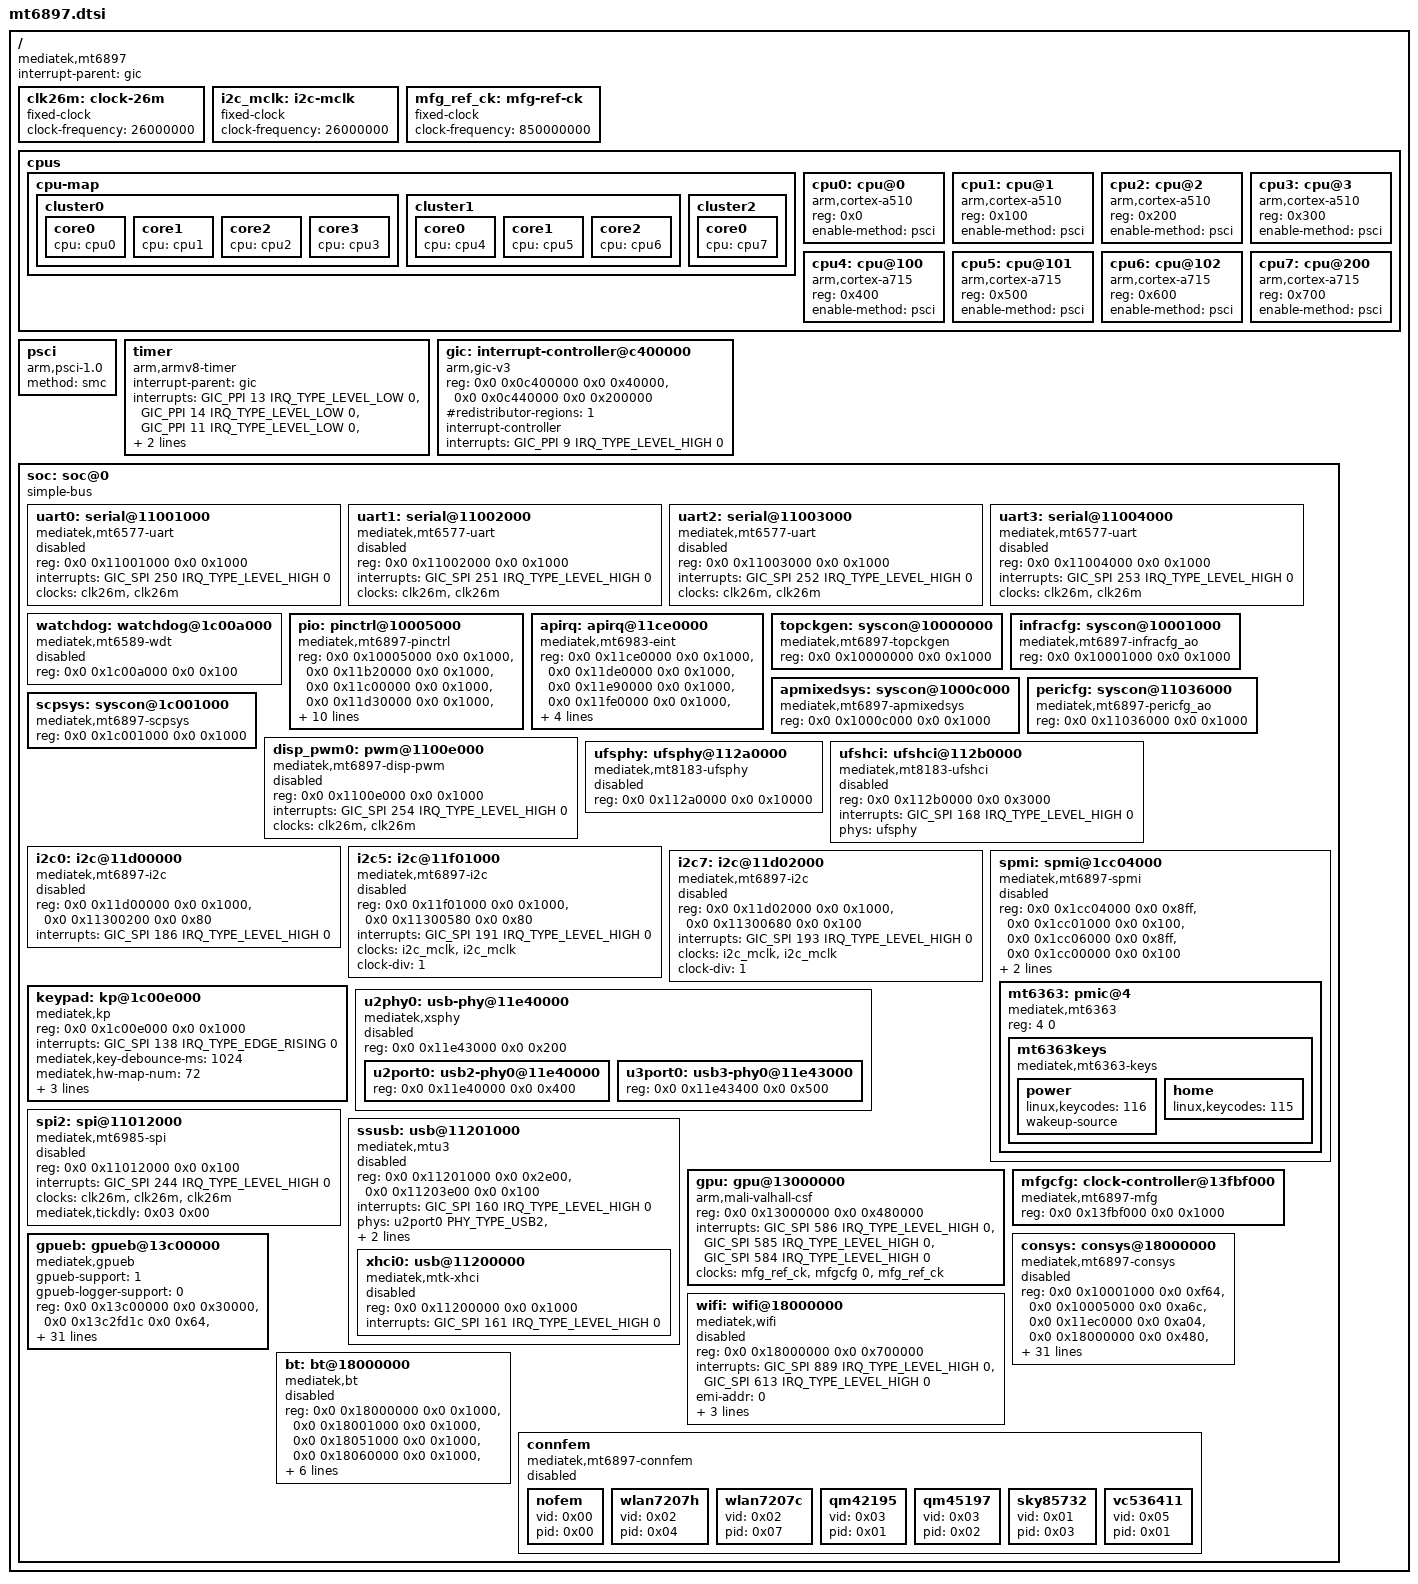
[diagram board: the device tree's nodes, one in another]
// SPDX-License-Identifier: GPL-2.0 OR BSD-3-Clause
/*
 * MediaTek MT6897 (MT8792) SoC — mainline bring-up, stage S1.
 *
 * 每一个数值都取自设备 bootloader 实际传入的 FDT
 * (reports/20260910-recovery/board.dtb)，那是最可信的硬件事实源。
 * 不确定的（时钟树编号、引脚表、电源域编号）先不写，等驱动落地再补。
 *
 * 单元数：厂商 DTB 的 / 与 /soc 都是 #address-cells=2 / #size-cells=2
 * （MT6895 主线移植用 1/1，直接套到这颗 SoC 上会错），本文件跟随厂商。
 * 中断单元数同理是 4（末位是 0），不是主线的 3。
 *
 * ⚠️ GIC 基址有家族惯例与本机的冲突，见下方 gic 节点的注释。
 */

#include <dt-bindings/interrupt-controller/arm-gic.h>
#include <dt-bindings/interrupt-controller/irq.h>
#include <dt-bindings/phy/phy.h>
#include <dt-bindings/gpio/gpio.h>

/ {
	compatible = "mediatek,mt6897";
	#address-cells = <2>;
	#size-cells = <2>;

	interrupt-parent = <&gic>;

	/* 没有时钟驱动前的临时时钟源：给 UART 用，让早期控制台能出字 */
	clk26m: clock-26m {
		compatible = "fixed-clock";
		#clock-cells = <0>;
		clock-frequency = <26000000>;
	};

	/*
	 * I2C 模块时钟占位（主线暂无 MT6897 topckgen 驱动）。
	 * i2c-mt65xx 用 clk_get_rate("main") 算分频：SCL = f_real / (2 * div)，
	 * 而 div 是按 f_assumed 算出来的 ⇒ SCL_actual = 目标频率 × f_real / f_assumed。
	 * 故意把 f_assumed 取大：真实模块时钟若比它低，实际 SCL 只会更慢（安全方向）。
	 * 真实频率待 recovery 侧 /sys/kernel/debug/clk/clk_summary 实测后修正。
	 */
	i2c_mclk: i2c-mclk {
		compatible = "fixed-clock";
		#clock-cells = <0>;
		clock-frequency = <26000000>;
	};

	/*
	 * MFG 参考时钟：mfgcfg BG3D gate 的父时钟。
	 * 主线暂无 MT6897 topckgen 驱动，先用 fixed-clock 占位（LK/preloader
	 * 已经把 MFGPLL 跑起来了，真实频率约 850MHz）。
	 */
	mfg_ref_ck: mfg-ref-ck {
		compatible = "fixed-clock";
		#clock-cells = <0>;
		clock-frequency = <850000000>;
	};

	cpus {
		#address-cells = <1>;
		#size-cells = <0>;

		cpu-map {
			cluster0 {
				core0 { cpu = <&cpu0>; };
				core1 { cpu = <&cpu1>; };
				core2 { cpu = <&cpu2>; };
				core3 { cpu = <&cpu3>; };
			};
			cluster1 {
				core0 { cpu = <&cpu4>; };
				core1 { cpu = <&cpu5>; };
				core2 { cpu = <&cpu6>; };
			};
			cluster2 {
				core0 { cpu = <&cpu7>; };
			};
		};

		/* 4x Cortex-A510（厂商 DTB 里每个核各占一个 cluster 位） */
		cpu0: cpu@0 {
			device_type = "cpu";
			compatible = "arm,cortex-a510";
			reg = <0x0>;
			enable-method = "psci";
		};
		cpu1: cpu@1 {
			device_type = "cpu";
			compatible = "arm,cortex-a510";
			reg = <0x100>;
			enable-method = "psci";
		};
		cpu2: cpu@2 {
			device_type = "cpu";
			compatible = "arm,cortex-a510";
			reg = <0x200>;
			enable-method = "psci";
		};
		cpu3: cpu@3 {
			device_type = "cpu";
			compatible = "arm,cortex-a510";
			reg = <0x300>;
			enable-method = "psci";
		};

		/* 3x + 1x Cortex-A715 */
		cpu4: cpu@100 {
			device_type = "cpu";
			compatible = "arm,cortex-a715";
			reg = <0x400>;
			enable-method = "psci";
		};
		cpu5: cpu@101 {
			device_type = "cpu";
			compatible = "arm,cortex-a715";
			reg = <0x500>;
			enable-method = "psci";
		};
		cpu6: cpu@102 {
			device_type = "cpu";
			compatible = "arm,cortex-a715";
			reg = <0x600>;
			enable-method = "psci";
		};
		cpu7: cpu@200 {
			device_type = "cpu";
			compatible = "arm,cortex-a715";
			reg = <0x700>;
			enable-method = "psci";
		};
	};

	psci {
		compatible = "arm,psci-1.0";
		method = "smc";
	};

	timer {
		compatible = "arm,armv8-timer";
		interrupt-parent = <&gic>;
		interrupts = <GIC_PPI 13 IRQ_TYPE_LEVEL_LOW 0>,
			     <GIC_PPI 14 IRQ_TYPE_LEVEL_LOW 0>,
			     <GIC_PPI 11 IRQ_TYPE_LEVEL_LOW 0>,
			     <GIC_PPI 10 IRQ_TYPE_LEVEL_LOW 0>;
		clock-frequency = <13000000>;
	};

	/*
	 * ⚠️ GIC 基址：厂商 DTB 的 /interrupt-controller 是
	 *      0x0c400000 (dist, 0x40000) + 0x0c440000 (redist, 0x200000)
	 *    而主线 MTK 全家族（mt6895 / mt8195 / mt8192 / mt8183）都在 0x0c000000，
	 *    本机另有一个 mediatek,gic500 节点占着 0x0c000000+0x400000。
	 *
	 *    这里以厂商 DTB 为准（那是设备真在跑的配置）。
	 *    若内核起不来（卡在 Calibrating / no timer），把下面两行换成：
	 *        <0x0 0x0c000000 0x0 0x40000>,
	 *        <0x0 0x0c040000 0x0 0x200000>;
	 *    这两种各出一个 dtb 去试，是最经济的排查方式。
	 */
	gic: interrupt-controller@c400000 {
		compatible = "arm,gic-v3";
		reg = <0x0 0x0c400000 0x0 0x40000>,
		      <0x0 0x0c440000 0x0 0x200000>;
		#interrupt-cells = <4>;
		#address-cells = <2>;
		#size-cells = <2>;
		#redistributor-regions = <1>;
		interrupt-controller;
		interrupts = <GIC_PPI 9 IRQ_TYPE_LEVEL_HIGH 0>;
	};

	soc: soc@0 {
		compatible = "simple-bus";
		#address-cells = <2>;
		#size-cells = <2>;
		ranges;

		/*
		 * 串口：兼容 "mediatek,mt6577-uart"，主线 8250_mtk 直接支持。
		 * 但物理上 UART0 接在键盘底座排线上，且厂商 cmdline 有
		 * mtk_printk_ctrl.disable_uart=1 —— 所以 S1 不指望串口，
		 * 真正的控制台走 simple-framebuffer + fbcon（见板级 DTS）。
		 * IRQ：厂商 DTB 是 SPI 250/251/252/253，不是 MT6895 的 141。
		 */
		uart0: serial@11001000 {
			compatible = "mediatek,mt6577-uart";
			reg = <0x0 0x11001000 0x0 0x1000>;
			interrupts = <GIC_SPI 250 IRQ_TYPE_LEVEL_HIGH 0>;
			clocks = <&clk26m>, <&clk26m>;
			clock-names = "baud", "bus";
			status = "disabled";
		};
		uart1: serial@11002000 {
			compatible = "mediatek,mt6577-uart";
			reg = <0x0 0x11002000 0x0 0x1000>;
			interrupts = <GIC_SPI 251 IRQ_TYPE_LEVEL_HIGH 0>;
			clocks = <&clk26m>, <&clk26m>;
			clock-names = "baud", "bus";
			status = "disabled";
		};
		uart2: serial@11003000 {
			compatible = "mediatek,mt6577-uart";
			reg = <0x0 0x11003000 0x0 0x1000>;
			interrupts = <GIC_SPI 252 IRQ_TYPE_LEVEL_HIGH 0>;
			clocks = <&clk26m>, <&clk26m>;
			clock-names = "baud", "bus";
			status = "disabled";
		};
		uart3: serial@11004000 {
			compatible = "mediatek,mt6577-uart";
			reg = <0x0 0x11004000 0x0 0x1000>;
			interrupts = <GIC_SPI 253 IRQ_TYPE_LEVEL_HIGH 0>;
			clocks = <&clk26m>, <&clk26m>;
			clock-names = "baud", "bus";
			status = "disabled";
		};

		/* 看门狗：厂商 compatible 含 mediatek,mt6589-wdt，主线 mtk_wdt 已支持 */
		watchdog: watchdog@1c00a000 {
			compatible = "mediatek,mt6589-wdt";
			reg = <0x0 0x1c00a000 0x0 0x100>;
			status = "disabled";
		};

		/*
		 * 以下节点先把「地址事实」登记下来，全部 status = "disabled"。
		 * 等 clk-mt6897 / pinctrl-mt6897 落地后再逐个启用。
		 */

		/* 引脚控制器（厂商 DTB 10 段 reg + 同名 reg-names） */
		pio: pinctrl@10005000 {
			compatible = "mediatek,mt6897-pinctrl";
			reg = <0x0 0x10005000 0x0 0x1000>,
			      <0x0 0x11b20000 0x0 0x1000>,
			      <0x0 0x11c00000 0x0 0x1000>,
			      <0x0 0x11d30000 0x0 0x1000>,
			      <0x0 0x11d40000 0x0 0x1000>,
			      <0x0 0x11d50000 0x0 0x1000>,
			      <0x0 0x11ea0000 0x0 0x1000>,
			      <0x0 0x11eb0000 0x0 0x1000>,
			      <0x0 0x11f20000 0x0 0x1000>,
			      <0x0 0x11f30000 0x0 0x1000>;
			reg-names = "gpio", "iocfg_rt", "iocfg_rm",
				    "iocfg_bl", "iocfg_bm", "iocfg_br",
				    "iocfg_lb", "iocfg_lt", "iocfg_tm",
				    "iocfg_tl";
			gpio-controller;
			#gpio-cells = <2>;
			gpio-ranges = <&pio 0 0 232>;
			interrupt-controller;
			#interrupt-cells = <2>;
			mediatek,eint = <&apirq>;
		};

		/*
		 * EINT 五段寄存器组（厂商 DTB apirq@11ce0000，reg-name
		 * 顺序 eint-e/s/w/n/c，与 mt6895 的 w/e/s/n/c 不同）。
		 * EINT 号 -> (bank, index) 矩阵在 pinctrl-mt6897.c 内。
		 */
		apirq: apirq@11ce0000 {
			compatible = "mediatek,mt6983-eint";
			reg = <0x0 0x11ce0000 0x0 0x1000>,
			      <0x0 0x11de0000 0x0 0x1000>,
			      <0x0 0x11e90000 0x0 0x1000>,
			      <0x0 0x11fe0000 0x0 0x1000>,
			      <0x0 0x1c01e000 0x0 0x1000>;
			reg-names = "eint-e", "eint-s", "eint-w",
				    "eint-n", "eint-c";
			interrupts = <GIC_SPI 309 IRQ_TYPE_LEVEL_HIGH 0>;
			mediatek,total-pin-number = <250>;
			mediatek,instance-num = <5>;
		};

		/* 时钟/系统控制寄存器（先登记，等 clk-mt6897） */
		topckgen: syscon@10000000 {
			compatible = "mediatek,mt6897-topckgen", "syscon";
			reg = <0x0 0x10000000 0x0 0x1000>;
			#clock-cells = <1>;
		};
		infracfg: syscon@10001000 {
			compatible = "mediatek,mt6897-infracfg_ao", "syscon";
			reg = <0x0 0x10001000 0x0 0x1000>;
			#clock-cells = <1>;
		};
		apmixedsys: syscon@1000c000 {
			compatible = "mediatek,mt6897-apmixedsys", "syscon";
			reg = <0x0 0x1000c000 0x0 0x1000>;
			#clock-cells = <1>;
		};
		pericfg: syscon@11036000 {
			compatible = "mediatek,mt6897-pericfg_ao", "syscon";
			reg = <0x0 0x11036000 0x0 0x1000>;
			#clock-cells = <1>;
		};
		scpsys: syscon@1c001000 {
			compatible = "mediatek,mt6897-scpsys", "syscon";
			reg = <0x0 0x1c001000 0x0 0x1000>;
			#power-domain-cells = <1>;
		};

		disp_pwm0: pwm@1100e000 {
			compatible = "mediatek,mt6897-disp-pwm";
			reg = <0x0 0x1100e000 0x0 0x1000>;
			interrupts = <GIC_SPI 254 IRQ_TYPE_LEVEL_HIGH 0>;
			clocks = <&clk26m>, <&clk26m>;
			clock-names = "main", "mm";
			#pwm-cells = <2>;
			status = "disabled";
		};

		/*
		 * UFS —— 厂商直接用主线的 "mediatek,mt8183-ufshci" / "-ufsphy"，
		 * 也就是 drivers/ufs/host/ufs-mediatek.c 已经是正确驱动，
		 * 我们要做的只是补时钟/电源域，不必新写 UFS 驱动。
		 */
		ufsphy: ufsphy@112a0000 {
			compatible = "mediatek,mt8183-ufsphy";
			reg = <0x0 0x112a0000 0x0 0x10000>;
			#phy-cells = <0>;
			status = "disabled";
		};
		ufshci: ufshci@112b0000 {
			compatible = "mediatek,mt8183-ufshci";
			reg = <0x0 0x112b0000 0x0 0x3000>;
			interrupts = <GIC_SPI 168 IRQ_TYPE_LEVEL_HIGH 0>;
			phys = <&ufsphy>;
			phy-names = "ufsphy";
			status = "disabled";
		};

		/* I2C（厂商 compatible 是 mt6897-i2c，主线需补 of_device_id） */
		i2c0: i2c@11d00000 {
			compatible = "mediatek,mt6897-i2c";
			reg = <0x0 0x11d00000 0x0 0x1000>,
			      <0x0 0x11300200 0x0 0x80>;
			interrupts = <GIC_SPI 186 IRQ_TYPE_LEVEL_HIGH 0>;
			#address-cells = <1>;
			#size-cells = <0>;
			status = "disabled";
		};
		/*
		 * i2c5 = 0x11f01000：外置充电 IC mt6375@0x34（厂商同名 i2c5）
		 * i2c7 = 0x11d02000：电量计 mm8013@0x55（厂商同名 i2c7）+ fsa4480@0x43
		 * 第二个 reg 是 APDMA 同步寄存器 —— mt6895_compat.apdma_sync = 1，必需。
		 */
		i2c5: i2c@11f01000 {
			compatible = "mediatek,mt6897-i2c";
			reg = <0x0 0x11f01000 0x0 0x1000>,
			      <0x0 0x11300580 0x0 0x80>;
			interrupts = <GIC_SPI 191 IRQ_TYPE_LEVEL_HIGH 0>;
			clocks = <&i2c_mclk>, <&i2c_mclk>;
			clock-names = "main", "dma";
			clock-div = <1>;
			#address-cells = <1>;
			#size-cells = <0>;
			status = "disabled";
		};

		i2c7: i2c@11d02000 {
			compatible = "mediatek,mt6897-i2c";
			reg = <0x0 0x11d02000 0x0 0x1000>,
			      <0x0 0x11300680 0x0 0x100>;
			interrupts = <GIC_SPI 193 IRQ_TYPE_LEVEL_HIGH 0>;
			clocks = <&i2c_mclk>, <&i2c_mclk>;
			clock-names = "main", "dma";
			clock-div = <1>;
			#address-cells = <1>;
			#size-cells = <0>;
			status = "disabled";
		};

		/* SPMI（MT6363 PMIC 挂这条总线：按键/电量计/温控全在这上面） */
		spmi: spmi@1cc04000 {
			compatible = "mediatek,mt6897-spmi";
			reg = <0x0 0x1cc04000 0x0 0x8ff>,
			      <0x0 0x1cc01000 0x0 0x100>,
			      <0x0 0x1cc06000 0x0 0x8ff>,
			      <0x0 0x1cc00000 0x0 0x100>;
			reg-names = "pmif", "spmimst", "pmif-p", "spmimst-p";
			clocks = <&clk26m>, <&clk26m>, <&clk26m>;
			clock-names = "pmif_sys_ck", "pmif_tmr_ck", "spmimst_clk_mux";
			/* PMIC INT 线走 GPIO EINT 248（原厂 DTB 实测），但 MT6897 的
			 * EINT 编码与我们的 4-cell GIC 对不上、且 pinctrl 驱动未落地，
			 * 刻意不接 upstream 中断：mtk-spmi-pmic 拿不到 irq 时降级为
			 * 轮询模式。interrupt-controller/#interrupt-cells 保留 ——
			 * spmi 本身仍是 PMIC 子设备（按键/温控）的中断父。 */
			interrupt-controller;
			#interrupt-cells = <1>;
			#address-cells = <2>;
			#size-cells = <0>;
			status = "disabled";

			mt6363: pmic@4 {
				compatible = "mediatek,mt6363";
				reg = <4 0>;

				mt6363keys: mt6363keys {
					compatible = "mediatek,mt6363-keys";
					power {
						linux,keycodes = <116>;
						wakeup-source;
					};

					home {
						linux,keycodes = <115>;
					};
				};
			};
		};

		/* Keypad 控制器（音量键等） */
		keypad: kp@1c00e000 {
			compatible = "mediatek,kp";
			reg = <0x0 0x1c00e000 0x0 0x1000>;
			interrupts = <GIC_SPI 138 IRQ_TYPE_EDGE_RISING 0>;
			mediatek,key-debounce-ms = <1024>;
			mediatek,hw-map-num = <72>;
			mediatek,hw-init-map = <
				114 249 0 0 0 0 0 0 0
				0 0 0 0 0 0 0 0 0
				0 0 0 0 0 0 0 0 0
				0 0 0 0 0 0 0 0 0
				0 0 0 0 0 0 0 0 0
				0 0 0 0 0 0 0 0 0
				0 0 0 0 0 0 0 0 0
				0 0 0 0 0 0 0 0 0
			>;
			clocks = <&clk26m>;
			clock-names = "kpd";
			status = "okay";
		};

		u2phy0: usb-phy@11e40000 {
			compatible = "mediatek,xsphy";
			reg = <0x0 0x11e43000 0x0 0x200>;
			#address-cells = <2>;
			#size-cells = <2>;
			ranges;
			status = "disabled";

			u2port0: usb2-phy0@11e40000 {
				reg = <0x0 0x11e40000 0x0 0x400>;
				#phy-cells = <1>;
			};

			u3port0: usb3-phy0@11e43000 {
				reg = <0x0 0x11e43400 0x0 0x500>;
				#phy-cells = <1>;
			};
		};

		spi2: spi@11012000 {
			compatible = "mediatek,mt6985-spi", "mediatek,mt6983-spi";
			reg = <0x0 0x11012000 0x0 0x100>;
			interrupts = <GIC_SPI 244 IRQ_TYPE_LEVEL_HIGH 0>;
			clocks = <&clk26m>, <&clk26m>, <&clk26m>;
			clock-names = "parent-clk", "sel-clk", "spi-clk";
			/* 首条 compatible 命中 mt6985_compat（无 need_pad_sel），
			 * mediatek,pad-select 不会被驱动读取，故不写。 */
			mediatek,tickdly = <0x03 0x00>;
			#address-cells = <1>;
			#size-cells = <0>;
			status = "disabled";
		};

		ssusb: usb@11201000 {
			compatible = "mediatek,mtu3";
			reg = <0x0 0x11201000 0x0 0x2e00>,
			      <0x0 0x11203e00 0x0 0x100>;
			reg-names = "mac", "ippc";
			interrupts = <GIC_SPI 160 IRQ_TYPE_LEVEL_HIGH 0>;
			phys = <&u2port0 PHY_TYPE_USB2>, <&u3port0 PHY_TYPE_USB3>;
			#address-cells = <2>;
			#size-cells = <2>;
			ranges;
			dr_mode = "host";
			status = "disabled";

			xhci0: usb@11200000 {
				compatible = "mediatek,mtk-xhci";
				reg = <0x0 0x11200000 0x0 0x1000>;
				reg-names = "mac";
				interrupts = <GIC_SPI 161 IRQ_TYPE_LEVEL_HIGH 0>;
				status = "disabled";
			};
		};

		/*
		 * GPU：Mali-G615 MC6 (Valhall CSF 架构)。
		 * 主线驱动为 panthor (arm,mali-valhall-csf)。
		 * 中断号与厂商 DT 一致（JOB=586, MMU=585, GPU=584）。
		 */
		gpu: gpu@13000000 {
			compatible = "arm,mali-valhall-csf";
			reg = <0x0 0x13000000 0x0 0x480000>;
			interrupts = <GIC_SPI 586 IRQ_TYPE_LEVEL_HIGH 0>,
				     <GIC_SPI 585 IRQ_TYPE_LEVEL_HIGH 0>,
				     <GIC_SPI 584 IRQ_TYPE_LEVEL_HIGH 0>;
			interrupt-names = "job", "mmu", "gpu";
			/*
			 * 与 MT6895 参考树一致：core/coregroup/stacks。
			 * coregroup = mfgcfg 的 BG3D gate —— 缺它 clk_disable_unused()
			 * 会把 gate 关掉、GPU 跑起来后报 SError。
			 */
			clocks = <&mfg_ref_ck>, <&mfgcfg 0>, <&mfg_ref_ck>;
			clock-names = "core", "coregroup", "stacks";
			status = "okay";
		};

		/* MFG 配置块（GPU 的 BG3D gate + MFG bring-up 驱动） */
		mfgcfg: clock-controller@13fbf000 {
			compatible = "mediatek,mt6897-mfg";
			reg = <0x0 0x13fbf000 0x0 0x1000>;
			#clock-cells = <1>;
		};

		/*
		 * GPUEB（GPU Event Buffer）：GPU 电源/频率协处理器。
		 * panthor 用 mtk_ipi 请它给 GPU 上电（MT6895 参考树的做法）。
		 * 节点/表格取自厂商 DTB /soc/gpueb@13c00000。
		 *
		 * ⚠ 厂商 recv-table 在 DTB 里是 11×5 个 cell（实测 fdtget = 55），
		 *   而主线 gpueb 驱动按 4 元组解析（recv_item_num=4），所以这里取
		 *   每组前 4 个。前 8 组与 mt6895 参考表逐项一致，可信。
		 */
		gpueb: gpueb@13c00000 {
			compatible = "mediatek,gpueb";
			gpueb-support = <1>;
			gpueb-logger-support = <0>;

			reg = <0x0 0x13c00000 0x0 0x30000>,
			      <0x0 0x13c2fd1c 0x0 0x64>,
			      <0x0 0x13c60000 0x0 0x2000>,
			      <0x0 0x13c2fd80 0x0 0x280>,
			      <0x0 0x13c62004 0x0 0x4>,
			      <0x0 0x13c62074 0x0 0x4>,
			      <0x0 0x13c62000 0x0 0x4>,
			      <0x0 0x13c62078 0x0 0x4>;
			reg-names = "gpueb_base", "gpueb_gpr_base",
				    "gpueb_reg_base", "mbox0_base",
				    "mbox0_set", "mbox0_clr",
				    "mbox0_send", "mbox0_recv";

			interrupts = <GIC_SPI 588 IRQ_TYPE_LEVEL_HIGH 0>;
			interrupt-names = "mbox0";

			mbox_count = <1>;
			mbox_size = <0xa0>;
			slot_size = <4>;
			ts_mbox = <0>;

			send_table =
				<0 0 4>, <1 0 8>, <2 0 3>, <3 0 6>,
				<4 0 9>, <5 0 4>, <6 0 6>, <7 0 6>,
				<8 0 1>, <9 0 4>, <10 0 3>;
			send_name_table =
				"IPI_ID_FAST_DVFS_EVENT", "IPI_ID_GPUFREQ",
				"IPI_ID_SLEEP", "IPI_ID_TIMER", "IPI_ID_FHCTL",
				"IPI_ID_CCF", "IPI_ID_GPUMPU", "IPI_ID_FAST_DVFS",
				"CH_IPIR_C_MET", "CH_IPIS_C_MET", "IPI_ID_BRISKET";

			recv_table =
				<0 0 4 0>, <1 0 8 1>, <2 0 1 0>, <3 0 1 0>,
				<4 0 1 1>, <5 0 4 1>, <6 0 1 1>, <7 0 6 1>,
				<8 0 4 0>, <9 0 1 1>, <10 0 3 1>;
			recv_name_table =
				"IPI_ID_FAST_DVFS_EVENT", "IPI_ID_GPUFREQ",
				"IPI_ID_SLEEP", "IPI_ID_TIMER", "IPI_ID_FHCTL",
				"IPI_ID_CCF", "IPI_ID_GPUMPU", "IPI_ID_FAST_DVFS",
				"CH_IPIR_C_MET", "CH_IPIS_C_MET", "IPI_ID_BRISKET";

			/* 厂商 me_GPUEB_SHARED 保留区：0x7fe70000 + 0x180000（本板 no-map） */
			gpueb_mem_addr = <0x0 0x7fe70000>;
			gpueb_mem_size = <0x0 0x180000>;
			gpueb_mem_table =
				<0 0x4000>,
				<1 0x140000>;
			gpueb_mem_name_table = "MEM_ID_GPUFREQ", "MEM_ID_LOG";

			status = "okay";
		};

		/*
		 * MT6897 连接性（WiFi / 蓝牙 / GNSS）—— 原厂硬件节点
		 */
		consys: consys@18000000 {
			compatible = "mediatek,mt6897-consys";
			#thermal-sensor-cells = <0>;
			reg = <0x0 0x10001000 0x0 0xf64>,
			      <0x0 0x10005000 0x0 0xa6c>,
			      <0x0 0x11ec0000 0x0 0xa04>,
			      <0x0 0x18000000 0x0 0x480>,
			      <0x0 0x18001000 0x0 0x658>,
			      <0x0 0x18003000 0x0 0x204>,
			      <0x0 0x1800e000 0x0 0x124>,
			      <0x0 0x18011000 0x0 0x138>,
			      <0x0 0x18012000 0x0 0xbc>,
			      <0x0 0x18020000 0x0 0x4c>,
			      <0x0 0x18023000 0x0 0x1000>,
			      <0x0 0x1803b000 0x0 0x18>,
			      <0x0 0x18040000 0x0 0x2c>,
			      <0x0 0x18041000 0x0 0x164>,
			      <0x0 0x18042000 0x0 0x324>,
			      <0x0 0x1804b000 0x0 0x414>,
			      <0x0 0x1804d000 0x0 0x41c>,
			      <0x0 0x1804f000 0x0 0x148>,
			      <0x0 0x18053800 0x0 0x1000>,
			      <0x0 0x18060000 0x0 0xbf8>,
			      <0x0 0x18070000 0x0 0x8004>,
			      <0x0 0x1c001000 0x0 0x1000>,
			      <0x0 0x1c00a000 0x0 0x51c>,
			      <0x0 0x1803c000 0x0 0x04>,
			      <0x0 0x1803e000 0x0 0x04>;
			emi-addr = <0>;
			emi-size = <0xc00000>;
			ro-bt-emi-size = <0x2e0000>;
			ro-gps-emi-size = <0xa0000>;
			ro-wifi-emi-size = <0x300000>;
			ro-emi-size = <0x680000>;
			rw-emi-size = <0x480000>;
			emi-alignment = <0x100000>;
			emi-max-addr = <0x90000000>;
			tcxo_support = "false";
			status = "disabled";
		};

		wifi: wifi@18000000 {
			compatible = "mediatek,wifi";
			reg = <0x0 0x18000000 0x0 0x700000>;
			interrupts = <GIC_SPI 889 IRQ_TYPE_LEVEL_HIGH 0>,
				     <GIC_SPI 613 IRQ_TYPE_LEVEL_HIGH 0>;
			emi-addr = <0>;
			emi-size = <0x1400000>;
			emi-alignment = <0x1000000>;
			emi-max-addr = <0xc0000000>;
			status = "disabled";
		};

		bt: bt@18000000 {
			compatible = "mediatek,bt";
			reg = <0x0 0x18000000 0x0 0x1000>,
			      <0x0 0x18001000 0x0 0x1000>,
			      <0x0 0x18051000 0x0 0x1000>,
			      <0x0 0x18060000 0x0 0x1000>,
			      <0x0 0x18800000 0x0 0x1000>,
			      <0x0 0x18812000 0x0 0x1000>,
			      <0x0 0x10001000 0x0 0x1000>;
			interrupts = <GIC_SPI 892 IRQ_TYPE_LEVEL_HIGH 0>,
				     <GIC_SPI 614 IRQ_TYPE_LEVEL_HIGH 0>,
				     <GIC_SPI 891 IRQ_TYPE_LEVEL_HIGH 0>;
			status = "disabled";
		};

		connfem: connfem {
			compatible = "mediatek,mt6897-connfem";
			status = "disabled";

			nofem: nofem {
				vid = <0x00>;
				pid = <0x00>;
			};

			wlan7207h: wlan7207h {
				vid = <0x02>;
				pid = <0x04>;
			};

			wlan7207c: wlan7207c {
				vid = <0x02>;
				pid = <0x07>;
			};

			qm42195: qm42195 {
				vid = <0x03>;
				pid = <0x01>;
			};

			qm45197: qm45197 {
				vid = <0x03>;
				pid = <0x02>;
			};

			sky85732: sky85732 {
				vid = <0x01>;
				pid = <0x03>;
			};

			vc536411: vc536411 {
				vid = <0x05>;
				pid = <0x01>;
			};
		};
	};
};
